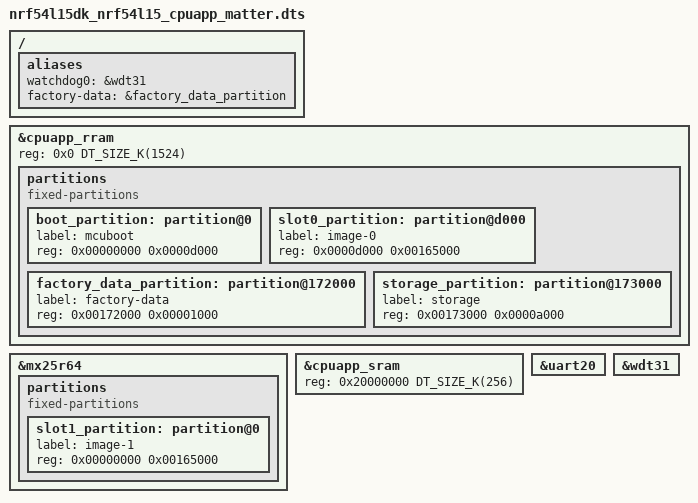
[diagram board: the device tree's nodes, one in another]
/*
 * Copyright (c) 2025 Nordic Semiconductor ASA
 *
 * SPDX-License-Identifier: LicenseRef-Nordic-5-Clause
 */

#include <../boards/nordic/nrf54l15dk/nrf54l15dk_nrf54l15_cpuapp.dts>

/delete-node/ &boot_partition;
/delete-node/ &slot0_partition;
/delete-node/ &slot1_partition;
/delete-node/ &storage_partition;

/ {
	aliases {
		watchdog0 = &wdt31;
		factory-data = &factory_data_partition;
	};
};

/* restore full RRAM and SRAM space - by default some parts are dedicated to FLRP */
&cpuapp_rram {
	reg = <0x0 DT_SIZE_K(1524)>;

	partitions {
		compatible = "fixed-partitions";
		#address-cells = <1>;
		#size-cells = <1>;

		boot_partition: partition@0 {
			label = "mcuboot";
			reg = <0x00000000 0x0000d000>;
		};

		slot0_partition: partition@d000 {
			label = "image-0";
			reg = <0x0000d000 0x00165000>;
		};

		factory_data_partition: partition@172000 {
			label = "factory-data";
			reg = <0x00172000 0x00001000>;
		};

		storage_partition: partition@173000 {
			label = "storage";
			reg = <0x00173000 0x0000a000>;
		};
	};
};

&mx25r64 {
	status = "okay";

	partitions {
		compatible = "fixed-partitions";
		#address-cells = <1>;
		#size-cells = <1>;

		slot1_partition: partition@0 {
			label = "image-1";
			reg = <0x00000000 0x00165000>;
		};
	};
};

&cpuapp_sram {
	reg = <0x20000000 DT_SIZE_K(256)>;
	ranges = <0x0 0x20000000  0x40000>;
};

/* TODO: re-enable HWFC once it's fixed */
&uart20 {
	/delete-property/ hw-flow-control;
};

&wdt31 {
	status = "okay";
};
